# CH564 register map
Vendor: WCH Ltd.; File version: 1.1
Registers are 8-bit, read-write, reset 0x0 unless marked. A register's access mark holds for its fields unless they carry their own. Offsets are from the block's base; [hi:lo] are bit positions.

## USBPD — USBPD configuration
Base 0x4040E000
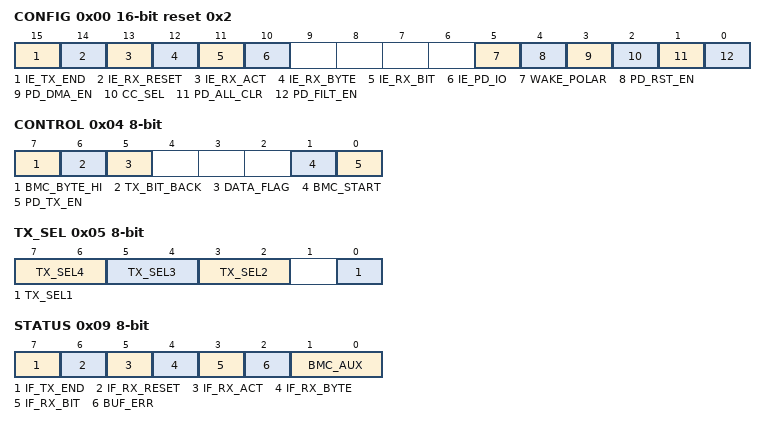
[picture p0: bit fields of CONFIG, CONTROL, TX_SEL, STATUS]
0x00 CONFIG 16-bit reset 0x2 — PD interrupt enable register
  [15] IE_TX_END — transfer complete register
  [14] IE_RX_RESET — Receive complete rst register
  [13] IE_RX_ACT — Receive complete register
  [12] IE_RX_BYTE — Receive byte register
  [11] IE_RX_BIT — bit interrupt Enable
  [10] IE_PD_IO — IO Enable
  [5] WAKE_POLAR — wakeup polarity
  [4] PD_RST_EN — PD mode reset command Enabled
  [3] PD_DMA_EN — PD DMA mode enabled
  [2] CC_SEL — PD Commutation port
  [1] PD_ALL_CLR — PD mode Clears all interrupt flags
  [0] PD_FILT_EN — PIN filtering enabled
0x02 BMC_CLK_CNT 16-bit — BMC sampling clock counter
  [8:0] BMC_CLK_CNT — R/T counter
0x04 CONTROL access per field — PD Send and receive enable register
  [7] BMC_BYTE_HI ro — BMC_BYTE_HI value
  [6] TX_BIT_BACK ro — TX_BIT_BACK value
  [5] DATA_FLAG ro — DATA_FLAG value
  [1] BMC_START rw — BMC_START value
  [0] PD_TX_EN rw — PD_TX_EN value
0x05 TX_SEL — SOP port selection register
  [7:6] TX_SEL4 — K-CODE4 type selection
  [5:4] TX_SEL3 — K-CODE3 type selection
  [3:2] TX_SEL2 — K-CODE2 type selection
  [0] TX_SEL1 — K-CODE1 type selection
0x06 BMC_TX_SZ 16-bit — PD send length register
  [8:0] BMC_TX_SZ — BMC_TX_SZ value
0x08 DATA_BUF ro — DMA cache data register
  [7:0] DATA_BUF — DATA_BUF value
0x09 STATUS — PD interrupt flag register
  [7] IF_TX_END — IF_TX_END value
  [6] IF_RX_RESET — IF_RX_RESET value
  [5] IF_RX_ACT — IF_RX_ACT value
  [4] IF_RX_BYTE — IF_RX_BYTE value
  [3] IF_RX_BIT — IF_RX_BIT value
  [2] BUF_ERR — BUF_ERR value
  [1:0] BMC_AUX — BMC_AUX value
0x0A BMC_BYTE_CNT 16-bit ro — Byte counter
  [8:0] BMC_BYTE_CNT — BMC_BYTE_CNT value
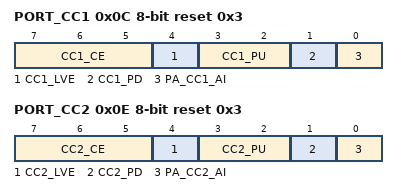
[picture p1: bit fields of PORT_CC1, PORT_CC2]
0x0C PORT_CC1 access per field reset 0x3 — CC1 port control register
  [7:5] CC1_CE rw — CC1 voltage comparator enable
  [4] CC1_LVE rw — CC1 port output of the low voltage
  [3:2] CC1_PU rw — CC1 port pull-up current selection
  [1] CC1_PD rw — CC1 port pull-down resistor enable
  [0] PA_CC1_AI ro — CC1 port comparator analog input
0x0E PORT_CC2 access per field reset 0x3 — CC2 port control register
  [7:5] CC2_CE rw — CC2 voltage comparator enable
  [4] CC2_LVE rw — CC2 port output of the low voltage
  [3:2] CC2_PU rw — CC2 port pull-up current selection
  [1] CC2_PD rw — CC2 port pull-down resistor enable
  [0] PA_CC2_AI ro — CC1 port comparator analog input
0x10 DMA 16-bit — PD buffer start address register
  [11:0] USBPD_DMA_ADDR — USBPD_DMA_ADDR value

## ADC
Base 0x4040A000
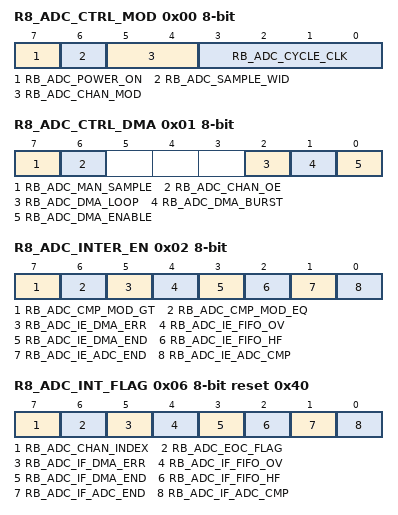
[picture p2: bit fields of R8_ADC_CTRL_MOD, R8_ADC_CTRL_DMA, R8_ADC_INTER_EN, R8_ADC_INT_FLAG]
0x00 R8_ADC_CTRL_MOD — ADC mode control register
  [7] RB_ADC_POWER_ON — ADC function enable
  [6] RB_ADC_SAMPLE_WID — ADC automatically samples the pulse width settings bit
  [5:4] RB_ADC_CHAN_MOD — ADC channel selection bit
  [3:0] RB_ADC_CYCLE_CLK — ADC clock sampling mode setting bit
0x01 R8_ADC_CTRL_DMA — DMA control register
  [7] RB_ADC_MAN_SAMPLE — ADC manually sampled the control bits
  [6] RB_ADC_CHAN_OE — ADC channel controls the ADCS output enable bits
  [2] RB_ADC_DMA_LOOP — DMA address loop function enables
  [1] RB_ADC_DMA_BURST — DMA block operation enable bit
  [0] RB_ADC_DMA_ENABLE — DMA function enable bit
0x02 R8_ADC_INTER_EN — ADC interrupt the enabling register
  [7] RB_ADC_CMP_MOD_GT — ADC reference size to compare enable bits
  [6] RB_ADC_CMP_MOD_EQ — ADC reference value equal comparable enable bits
  [5] RB_ADC_IE_DMA_ERR — DMA transfer process error response interrupt enable bits
  [4] RB_ADC_IE_FIFO_OV — FIFO overflow interruption enable bits
  [3] RB_ADC_IE_DMA_END — DMA ends the interrupt enable bits
  [2] RB_ADC_IE_FIFO_HF — FIFO receives half interrupt enable bits
  [1] RB_ADC_IE_ADC_END — ADC conversion complete interrupt enable bits
  [0] RB_ADC_IE_ADC_CMP — current ADC comparison activates the interrupt enable bits
0x03 R8_ADC_CLOCK_DIV reset 0x10 — ADC clock frequency partition coefficient register
  [7:0] ADC_CLOCK_DIV — sampling the clock frequency division coefficient
0x04 R16_ADC_DATA 16-bit ro — Convert the data register
  [11:0] ADC_DATA — ADC collected the data content
0x06 R8_ADC_INT_FLAG access per field reset 0x40 — Interrupt the status register
  [7] RB_ADC_CHAN_INDEX ro — The ADC current channel in autoconversion mode
  [6] RB_ADC_EOC_FLAG ro — The ADC transition-end state bit
  [5] RB_ADC_IF_DMA_ERR rw — DMA transfer error interrupt flag bit
  [4] RB_ADC_IF_FIFO_OV rw — FIFO overflow interrupt flag bit
  [3] RB_ADC_IF_DMA_END rw — DMA end flag bit
  [2] RB_ADC_IF_FIFO_HF rw — FIFO receives half interrupt flag bit
  [1] RB_ADC_IF_ADC_END rw — The ADC transition-end flag bit
  [0] RB_ADC_IF_ADC_CMP rw — ADC activated interrupt flag bits comparing the ADC current value with the reference
0x07 R8_ADC_FIFO_COUNT ro — FIFO count register
  [7:0] ADC_FIFO_COUNT — number of ADC converted data already stored in the FIFO
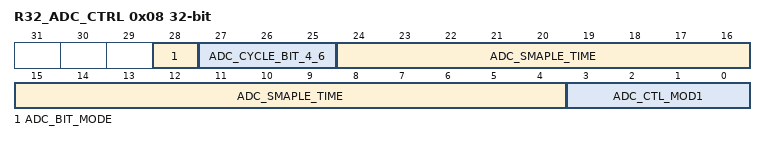
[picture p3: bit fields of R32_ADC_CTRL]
0x08 R32_ADC_CTRL 32-bit — ADC control register
  [28] ADC_BIT_MODE — ADC resolution selection bit
  [27:25] ADC_CYCLE_BIT_4_6 — Position 4-6 of the automatic sampling period
  [24:4] ADC_SMAPLE_TIME — ADC sampling and calibration time
  [3:0] ADC_CTL_MOD1 — Corresponding channel
0x0C R16_ADC_CMP_VALUE 16-bit — The comparison mode reference value register
  [11:0] ADC_CMP_VALUE — The comparison mode reference value
0x10 R16_ADC_FIFO 16-bit ro — ADC FIFO register
  [11:0] ADC_FIFO — ADC Current conversion value
0x14 R32_ADC_DMA_NOW 32-bit ro — DMA current buffer address register
  [17:0] ADC_DMA_NOW — DMA current buffer address
0x18 R32_ADC_DMA_BEG 32-bit — DMA start buffer address register
  [17:0] ADC_DMA_BEG — DMA start buffer address
0x1C R32_ADC_DMA_END 32-bit — DMA end buffer address register
  [17:0] R32_ADC_DMA_END — DMA end buffer address
